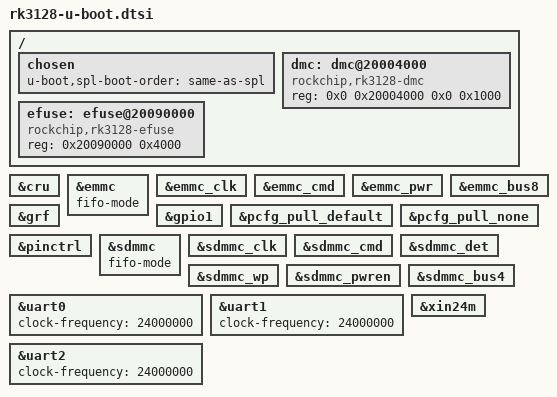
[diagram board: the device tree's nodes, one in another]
// SPDX-License-Identifier: GPL-2.0+

#include "rockchip-u-boot.dtsi"

/ {
	chosen {
		u-boot,spl-boot-order = "same-as-spl", &sdmmc, &emmc;
	};

	dmc: dmc@20004000 {
		compatible = "rockchip,rk3128-dmc", "syscon";
		reg = <0x0 0x20004000 0x0 0x1000>;
		bootph-all;
	};

	efuse: efuse@20090000 {
		compatible = "rockchip,rk3128-efuse";
		reg = <0x20090000 0x4000>;
	};
};

&cru {
	bootph-all;
};

&emmc {
	fifo-mode;
};

&emmc_clk {
	bootph-pre-ram;
	bootph-some-ram;
};

&emmc_cmd {
	bootph-pre-ram;
	bootph-some-ram;
};

&emmc_pwr {
	bootph-pre-ram;
	bootph-some-ram;
};

&emmc_bus8 {
	bootph-pre-ram;
	bootph-some-ram;
};

&gpio1 {
	bootph-pre-ram;
	bootph-some-ram;
};

&grf {
	bootph-all;
};

&pcfg_pull_default {
	bootph-all;
};

&pcfg_pull_none {
	bootph-all;
};

&pinctrl {
	bootph-all;
};

&sdmmc {
	bootph-pre-ram;
	bootph-some-ram;
	fifo-mode;
};

&sdmmc_clk {
	bootph-pre-ram;
	bootph-some-ram;
};

&sdmmc_cmd {
	bootph-pre-ram;
	bootph-some-ram;
};

&sdmmc_det {
	bootph-pre-ram;
	bootph-some-ram;
};

&sdmmc_wp {
	bootph-pre-ram;
	bootph-some-ram;
};

&sdmmc_pwren {
	bootph-pre-ram;
	bootph-some-ram;
};

&sdmmc_bus4 {
	bootph-pre-ram;
	bootph-some-ram;
};

&uart0 {
	clock-frequency = <24000000>;
};

&uart1 {
	clock-frequency = <24000000>;
};

&uart2 {
	clock-frequency = <24000000>;
};

&xin24m {
	bootph-all;
};
